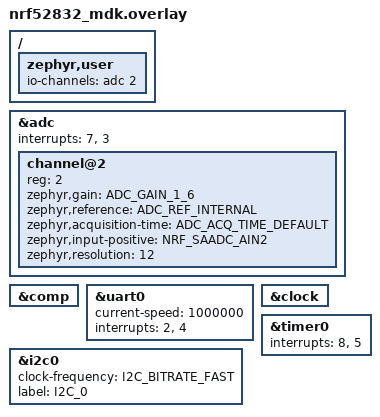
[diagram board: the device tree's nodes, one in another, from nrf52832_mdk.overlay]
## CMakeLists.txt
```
# SPDX-License-Identifier: Apache-2.0

cmake_minimum_required(VERSION 3.20.0)

find_package(Zephyr REQUIRED HINTS $ENV{ZEPHYR_BASE})
project(hello_world)

target_sources(app PRIVATE src/main.c)
target_sources(app PRIVATE src/soft_iic.c)
target_sources(app PRIVATE src/imu_bag.c)
target_sources(app PRIVATE src/timer.c)
target_sources(app PRIVATE src/adc.c)
```

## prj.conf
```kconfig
CONFIG_USE_SEGGER_RTT=y
CONFIG_RTT_CONSOLE=y
CONFIG_LED=y
CONFIG_LOG=y
CONFIG_PWM=y
CONFIG_LOG_MODE_IMMEDIATE=y
CONFIG_I2C=y
CONFIG_I2C_NRFX=y

CONFIG_NRFX_TIMER0=y
CONFIG_ADC=y
CONFIG_SYS_CLOCK_TICKS_PER_SEC=32768
```

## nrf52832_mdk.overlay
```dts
// To get started, press Ctrl+Space to bring up the completion menu and view the available nodes.

// You can also use the buttons in the sidebar to perform actions on nodes.
// Actions currently available include:

// * Enabling / disabling the node
// * Adding the bus to a bus
// * Removing the node
// * Connecting ADC channels

// For more help, browse the DeviceTree documentation at https://docs.zephyrproject.org/latest/guides/dts/index.html
// You can also visit the nRF DeviceTree extension documentation at https://nrfconnect.github.io/vscode-nrf-connect/devicetree/nrfdevicetree.html
/ {
	zephyr,user {
		io-channels = <&adc 2>;
	};
};
&adc {
	#address-cells = <1>;
	#size-cells = <0>;

	channel@2 {
		reg = <2>;
		zephyr,gain = "ADC_GAIN_1_6";
		zephyr,reference = "ADC_REF_INTERNAL";
		zephyr,acquisition-time = <ADC_ACQ_TIME_DEFAULT>;
		zephyr,input-positive = <NRF_SAADC_AIN2>; /* P0.04 */
		zephyr,resolution = <12>;
	};

	status = "okay";
	interrupts = <7>, <3>;
};
&comp {
	status = "okay";
};
&uart0 {
	current-speed = <1000000>;
	interrupts = <2>, <4>;
};

&i2c0 {
	clock-frequency = <I2C_BITRATE_FAST>;
	label = "I2C_0";
};

&clock {
	status = "okay";
};

&timer0 {
	status = "okay";
	interrupts = <8>, <5>;
};
```

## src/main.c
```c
/*
 * Copyright (c) 2012-2014 Wind River Systems, Inc.
 *
 * SPDX-License-Identifier: Apache-2.0
 */
#include "imu_bag.h"
#include "timer.h"
#include "adc.h"
#include "iic_twi.h"
#include "icm_42688.h"
#include "uart.h"
#include <stdio.h>
#include "zephyr/logging/log.h"
#include "nrfx_saadc.h"
#include <zephyr/kernel.h>

//定义IIC的设备名称
struct device *i2c_dev;
#define I2C_DEV_NAME "I2C_0"
//用于进行flag的调用
int flag =0;
//存储一定的AD进而来进行在一定下进行输送
int pd[100];
//用于imu的数据发送
int count =0;
int imu_flag =0;
int b = 0;
int c = 1;
//用于imu_bag计数
int a=0;
char a_a[10];
LOG_MODULE_REGISTER(adc, LOG_LEVEL_DBG);
#define CHANNEL_COUNT 1

static nrfx_saadc_channel_t single_channel = NRFX_SAADC_DEFAULT_CHANNEL_SE(NRF_SAADC_INPUT_AIN2 , 0);
static nrf_saadc_value_t buffer[CHANNEL_COUNT];
/*时钟校准*/
void Bsp_HFCLK_Init_Extern()
{
    NRF_CLOCK->EVENTS_HFCLKSTARTED = 0;
    NRF_CLOCK->TASKS_HFCLKSTART = 1;

    while (NRF_CLOCK->EVENTS_HFCLKSTARTED == 0)
    {
        // Do nothing.
    }
}
int adc_init2(void)
{
	Bsp_HFCLK_Init_Extern();
	nrfx_err_t err;
	//初始化 输入初始化的中断优秀级
	err = nrfx_saadc_init(NRFX_SAADC_DEFAULT_CONFIG_IRQ_PRIORITY);
	//配置通道的属性
	single_channel.channel_config.gain = NRF_SAADC_GAIN1_3;
	//显示通道的采样时间间隔
	LOG_INF("TIME=%d\r\n",single_channel.channel_config.acq_time);
	//nrfx_saadc_channel_config完成通道的配置
	err = nrfx_saadc_channel_config(&single_channel);
	//nrfx_saadc_channels_configured_get();记录了当前配置的通道配置情况
	uint32_t channels_mask = nrfx_saadc_channels_configured_get();
	LOG_INF("ADC channels mask: %d\n", channels_mask);
	//设置通道分辨率为12bit，不使用过采样，事件回调
	err = nrfx_saadc_simple_mode_set(channels_mask, NRF_SAADC_RESOLUTION_12BIT, NRF_SAADC_OVERSAMPLE_DISABLED, NULL);
	printk("this %d\n",err);
	//在开始 SAADC 转换之前，您需要调用此函数来设置一个缓冲区，SAADC 将把采样数据存储到这个缓冲区中。
	err = nrfx_saadc_buffer_set(buffer, CHANNEL_COUNT);
}

int adc_value_get(void)
{
	nrfx_err_t err;
	//nrfx_saadc_offset_calibrate(NULL);校准ADC的偏移量，这里不使用回调函数。
	err = nrfx_saadc_offset_calibrate(NULL);
	//nrfx_saadc_mode_trigger();开始采集数据。
	err = nrfx_saadc_mode_trigger();
	return buffer[0];
}
//转换成电压
int adc_to_voltage(int adc_value)
{
	// return (adc_value * 1800)/4096 ;
	return adc_value ;
}

int main(void)
{
	// //用于存储格式化字符串
	char str[200];
	// //字符指针
	char *P;
	int i=0,offset=0;

	//硬件IIC
	i2c_dev = device_get_binding(I2C_DEV_NAME);
	if(!i2c_dev)
	{
		printk("Failed\n");
		return 0;
	}else{
		printk("SUCCESS\n");
	}
	int err = i2c_configure(i2c_dev, I2C_SPEED_SET(I2C_SPEED_FAST));
    if (err) {
        printk("Failed to configure I2C device: %d\n", err);
        return 0;
    }
    printk("I2C device configured successfully\n");
	// 进行imu与bag的初始化
	imu_bag_init();
	// 进行adc初始化
	adc_init2();
	//进行串口初始化
	uart_init_slef();
	//进行定时器初始化 2k采样率 
 	timer1_init_enable();
	while (1)
	{
			if(imu_flag)
			{
			imu_flag =0;
			imu_bag_read_data();
			// for(i=0;i<100;i++)
			// {
			// 	offset += sprintf(str + offset, "%d,", pd[i]); // 将整数转换为字符串并拼接到str中
			// }
			// P=str;
			// print_uart(P);
			// offset=0;
			// }
		}else{
			//必须加否则会被优化
			c=1;
		}
	}

	// // // //用于存储格式化字符串
	// // char str[200];
	// // // //字符指针
	// // char *P;
	// // int i=0,offset=0;

	// //硬件IIC
	// // i2c_dev = device_get_binding(I2C_DEV_NAME);
	// // if(!i2c_dev)
	// // {
	// // 	printk("Failed\n");
	// // 	return 0;
	// // }else{
	// // 	printk("SUCCESS\n");
	// // }
	// // int err = i2c_configure(i2c_dev, I2C_SPEED_SET(I2C_SPEED_FAST));
    // // if (err) {
    // //     printk("Failed to configure I2C device: %d\n", err);
    // //     return 0;
    // // }
    // // printk("I2C device configured successfully\n");
	// // 进行imu与bag的初始化
	// // imu_bag_init();
	// // 进行adc初始化
	// adc_init();
	// //进行串口初始化
	// uart_init_slef();
	// //进行定时器初始化 2k采样率 
 	// timer1_init_enable();
	// while (1)
	// {
	// 		if(imu_flag)
	// 		{
	// 		imu_flag =0;
	// 		adc_read_data();
	// 		// imu_bag_read_data();
	// 		// for(i=0;i<100;i++)
	// 		// {
	// 		// 	offset += sprintf(str + offset, "%d,", pd[i]); // 将整数转换为字符串并拼接到str中
	// 		// }
	// 		// P=str;
	// 		// print_uart(P);
	// 		// offset=0;
	// 		// }
	// 	}else{
	// 		//必须加否则会被优化
	// 		c=1;
	// 	}
	// }

	// adc_init2();
	// while(1){
	// 	printk("vol=%d\r\n",adc_to_voltage(adc_value_get()));
	// 	k_msleep(100);
	// }
	// adc_init();
	// while(1){
	// 	adc_read_data();
	// 	k_msleep(1);
	// }
	return 0;
}
```

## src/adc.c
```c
/*
 * Copyright (c) 2020 Libre Solar Technologies GmbH
 *
 * SPDX-License-Identifier: Apache-2.0
 */
#include "adc.h"

/* Data of ADC io-channels specified in devicetree. */
static const struct adc_dt_spec adc_channels[] = {
    DT_FOREACH_PROP_ELEM(DT_PATH(zephyr_user), io_channels,
                         DT_SPEC_AND_COMMA)};
static int err;
// static uint32_t count = 0;
static uint16_t buf;
static struct adc_sequence sequence = {
    .buffer = &buf,
    /* buffer size in bytes, not number of samples */
    .buffer_size = sizeof(buf),
};
/**
 * @brief        adc初始化配置
 */
int adc_init(void)
{
    /* Configure channels individually prior to sampling. */
    for (size_t i = 0U; i < ARRAY_SIZE(adc_channels); i++)
    {
        if (!adc_is_ready_dt(&adc_channels[i]))
        {
            printk("ADC controller device %s not ready\n", adc_channels[i].dev->name);
            return 0;
        }

        err = adc_channel_setup_dt(&adc_channels[i]);
        if (err < 0)
        {
            printk("Could not setup channel #%d (%d)\n", i, err);
            return 0;
        }
        (void)adc_sequence_init_dt(&adc_channels[i], &sequence);
    }
    return 1;
}
/**
 * @brief        adc读取数据处理
 */
void adc_read_data(void)
{
	//用于存储格式化字符串
	char str[5];
	//字符指针
	char *ptr;

        // printk("ADC reading[%u]:\n", count++);
        for (size_t i = 0U; i < ARRAY_SIZE(adc_channels); i++)
        {
            int32_t val_mv;

            // printk("- %s, channel %d: ",
            //        adc_channels[i].dev->name,
            //        adc_channels[i].channel_id);
            // (void)adc_sequence_init_dt(&adc_channels[i], &sequence);
            err = adc_read(adc_channels[i].dev, &sequence);
            if (err < 0)
            {
                printk("Could not read (%d)\n", err);
                continue;
            }
            /*
             * If using differential mode, the 16 bit value
             * in the ADC sample buffer should be a signed 2's
             * complement value.
             */
            if (adc_channels[i].channel_cfg.differential)
            {
                val_mv = (int32_t)((int16_t)buf);
            }
            else
            {
                val_mv = (int32_t)buf;
            }
            // printk("ADC%\n" PRId32, val_mv);
            // printk("%d,", val_mv);

            //将整数格式化成指针
		    sprintf(str,"%d,",val_mv);
		    ptr =str;
    		print_uart(ptr);
            // printk("%d,",val_mv);

            //下列代码是将ADC原始值变换为mV
            // err = adc_raw_to_millivolts_dt(&adc_channels[i],
            //                                &val_mv);
            // /* conversion to mV may not be supported, skip if not */
            // if (err < 0)
            // {
            //     printk(" (value in mV not available)\n");
            // }
            // else
            // {
            //     printk(" = %" PRId32 " mV\n", val_mv);
            // }
        }
}
```

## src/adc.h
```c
/**
 * @file         adc.h
 * @details      用于定义adc采样API
 * @author       jjl
 */
#ifndef _ADC_H
#define _ADC_H
/*
===========================
头文件包括
===========================
*/
#include <inttypes.h>
#include <stddef.h>
#include <stdint.h>

#include <zephyr/device.h>
#include <zephyr/devicetree.h>
#include <zephyr/drivers/adc.h>
#include <zephyr/kernel.h>
#include <zephyr/sys/printk.h>
#include <zephyr/sys/util.h>
/*
===========================
宏定义包括
===========================
*/
#if !DT_NODE_EXISTS(DT_PATH(zephyr_user)) || \
    !DT_NODE_HAS_PROP(DT_PATH(zephyr_user), io_channels)
#error "No suitable devicetree overlay specified"
#endif

#define DT_SPEC_AND_COMMA(node_id, prop, idx) \
    ADC_DT_SPEC_GET_BY_IDX(node_id, idx),
/*
===========================
函数申明包括
===========================
*/
/**
 * @brief        adc初始化配置
 */
void adc_init(void);
/**
 * @brief        adc读取数据配置
 */
void adc_read_data(void);
#endif
```

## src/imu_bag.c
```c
/*
 * Copyright (c) 2012-2014 Wind River Systems, Inc.
 *
 * SPDX-License-Identifier: Apache-2.0
 */

#include "imu_bag.h"



uint8_t data[15];
uint8_t icm42688_data[15];
uint8_t lis3dml_data[15];
int16_t acc_data[3] = {0};
int16_t gyro_data[3] = {0};
int16_t mag_data[3] = {0};
uint32_t icm42688_timestamp = 0;
/**
 * @brief Read a sequence of bytes from a sensor registers 重新封装IIC的读取
 * 
 */
static void sensor_register_read(uint8_t sensor_addr, uint8_t reg_addr, uint8_t *data, uint8_t len)
{
	EspI2cReadBytes(sensor_addr, reg_addr, data, len);
}
/**
 * @brief Write a byte to a sensor register 重新封装IIC的写入
 */
static void sensor_register_write_byte(uint8_t sensor_addr, uint8_t reg_addr, uint8_t data)
{
	EspI2cWriteByte(sensor_addr, reg_addr, data);
}
/**
 * @brief icm (imu) 初始化写入命令
 */
void icm_init()
{
	sensor_register_write_byte(ICM_I2C_ADDR, ICM_BANK_SEL, 0);
	k_msleep(10);
	/* 读WHO_AM_I寄存器 */
	sensor_register_read(ICM_I2C_ADDR, ICM_WHO_AM_I, data, 1);
	printk("icm42688 read id:%X\n", data[0]);
	if (data[0] == ICM_ID)
	{
		printk("icm42688 ready!\n");
	}
	else
	{
		printk("icm42688 not found!\n");
	}
	/* 配置寄存器 */
	sensor_register_write_byte(ICM_I2C_ADDR, ICM_DEVICE_CONFIG, 0x01); // 软重启
	k_msleep(10);													   // 等待10ms

	sensor_register_write_byte(ICM_I2C_ADDR, ICM_POWER_MAG, 0x1F); // 开启陀螺仪和加速度计
	k_msleep(100);

	/* 配置FS和ODR */
	// sensor_register_write_byte(ICM_I2C_ADDR, ICM_GYRO_CONFIG0, 0x67); // 250dps,200Hz
	sensor_register_write_byte(ICM_I2C_ADDR, ICM_GYRO_CONFIG0, 0x66); // 250dps,1000Hz
	k_msleep(50);
	// sensor_register_write_byte(ICM_I2C_ADDR, ICM_ACCEL_CONFIG0, 0x47); // 4g, 100Hz（这里应为200Hz）
	sensor_register_write_byte(ICM_I2C_ADDR, ICM_ACCEL_CONFIG0, 0x46); // 4g, 1000Hz
	k_msleep(50);
	sensor_register_write_byte(ICM_I2C_ADDR, ICM_GYRO_ACCEL_CONFIG0, 0x55); // 20Hz BW
	k_msleep(50);
	printk("icm42688 gyr and acc config finished!");

	/* 开启时间戳 */
	sensor_register_write_byte(ICM_I2C_ADDR, ICM_TMST_CONFIG, 0x33);
	k_msleep(50);
}
/**
 * @brief lis3dml (bag) 初始化写入命令
 */
void lis3dml_init()
{
	/* 读WHO_AM_I寄存器 */
	sensor_register_read(LIS3MDL_I2C_ADDR_G, LIS3MDL_WHO_AM_I, data, 1);
	printk("lis3dml read id:%X\n", data[0]);
	if (data[0] == LIS3MDL_ID)
	{
		printk("lis3dml ready!");
	}
	else
	{
		printk("lis3dml not found!");
	}
	/* 软重启 */
	sensor_register_write_byte(LIS3MDL_I2C_ADDR_G, LIS3MDL_CTRL_REG2, 0x04);
	/* 延时 */
	k_msleep(50);
	/* 配置BDU */
	sensor_register_write_byte(LIS3MDL_I2C_ADDR_G, LIS3MDL_CTRL_REG5, 0x40);
	/* 延时 */
	k_msleep(50);
	/* 配置 */
	// sensor_register_write_byte(LIS3MDL_I2C_ADDR_G, LIS3MDL_CTRL_REG1, 0x60 | 0x1C); // X、Y轴high performance，80Hz(这个不太对应该是ultra-high-perfermance)
	sensor_register_write_byte(LIS3MDL_I2C_ADDR_G, LIS3MDL_CTRL_REG1, 0x40 | 0x02); // X、Y轴high performance，300H performance，80Hz
	sensor_register_write_byte(LIS3MDL_I2C_ADDR_G, LIS3MDL_CTRL_REG2, 0x00);		// ±4 gauss
	sensor_register_write_byte(LIS3MDL_I2C_ADDR_G, LIS3MDL_CTRL_REG3, 0x00);		// 连续转换模式
	sensor_register_write_byte(LIS3MDL_I2C_ADDR_G, LIS3MDL_CTRL_REG4, 0x0C);		// Z轴high performance
}
/**
 * @brief imu与bag 初始化程序
 */
 void imu_bag_init(void)
{
	I2cInit();
	/* 初始化icm42688 */
	icm_init();
	/* 初始化lis3dml */
	lis3dml_init();
}
/**
 * @brief imu与bag 读取程序
 */
void imu_bag_read_data( void)
{
	//用于存储格式化字符串
	char str_42688[120];
	char str_3dml[120];
	// 字符指针
	char *ptr_42688;
	char *ptr_3dml;

		/* ICM-42688-P 读数据 */
		sensor_register_write_byte(ICM_I2C_ADDR, ICM_BANK_SEL, 0);
		sensor_register_write_byte(ICM_I2C_ADDR, ICM_SIGNAL_PATH_RESET, 0x04);
		sensor_register_read(ICM_I2C_ADDR, ICM_ACCEL_DATA_X1, icm42688_data, 12);
		sensor_register_write_byte(ICM_I2C_ADDR, ICM_BANK_SEL, 1);
		// k_usleep(10);
		sensor_register_read(ICM_I2C_ADDR, ICM_TMSTVAL0, icm42688_data + 12, 3);

		/* LIS3DML读数据 */
		sensor_register_read(LIS3MDL_I2C_ADDR_G, LIS3MDL_OUT_X_L, lis3dml_data, 6);

		/* ICM42688打印数据 */
		acc_data[0] = (icm42688_data[0] << 8) + icm42688_data[1];
		acc_data[1] = (icm42688_data[2] << 8) + icm42688_data[3];
		acc_data[2] = (icm42688_data[4] << 8) + icm42688_data[5];

		gyro_data[0] = (icm42688_data[6] << 8) + icm42688_data[7];
		gyro_data[1] = (icm42688_data[8] << 8) + icm42688_data[9];
		gyro_data[2] = (icm42688_data[10] << 8) + icm42688_data[11];

		icm42688_timestamp = (icm42688_data[14] << 16) + (icm42688_data[13] << 8) + icm42688_data[12];

		// /* LIS3DML打印数据 */
		mag_data[0] = lis3dml_data[0] + (lis3dml_data[1] << 8);
		mag_data[1] = lis3dml_data[2] + (lis3dml_data[3] << 8);
		mag_data[2] = lis3dml_data[4] + (lis3dml_data[5] << 8);

		// 将上面两行数据直接用串口打印
		// 将整数格式化成指针
		sprintf(str_42688,"icm42688, acc_x:%d, acc_y:%d, acc_z:%d, gyr_x:%d, gyr_y:%d, gyr_z:%d, tick:%ld \n",acc_data[0], acc_data[1], acc_data[2],
			   gyro_data[0], gyro_data[1], gyro_data[2],(long int)icm42688_timestamp);
		// sprintf(str_42688,"tick:%ld\n",(long int)icm42688_timestamp);
		ptr_42688 = str_42688;
		print_uart(ptr_42688);
		// memset(str_42688,0,sizeof(str_42688));

		sprintf(str_3dml,"lis3dml, mag_x:%d, mag_y:%d, mag_z:%d\n",
			   mag_data[0], mag_data[1], mag_data[2]);
		ptr_3dml = str_3dml;
		print_uart(ptr_3dml);
		// memset(str_3dml,0,sizeof(str_3dml));
}
```

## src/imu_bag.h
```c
/**
 * @file         imu_bag.h
 * @details      用于定义imu与bag联合程序
 * @author       jjl
 */
#ifndef _IMU_BAG_H
#define _IMU_BAG_H

/*
===========================
头文件包括
===========================
*/
#include <stdio.h>
#include <zephyr/kernel.h>
#include <zephyr/drivers/gpio.h>
#include <nrfx_gpiote.h>
#include "soft_iic.h"
#include "icm_42688.h"
#include "lis3dml.h"
/*
===========================
宏定义
===========================
*/
/* 1000 msec = 1 sec */
#define SLEEP_TIME_MS 1000
/*
===========================
变量声明
===========================
*/
extern uint8_t icm42688_data[15];
extern uint8_t lis3dml_data[15];
extern int16_t acc_data[3];
extern int16_t gyro_data[3];
extern int16_t mag_data[3];
extern uint32_t icm42688_timestamp;
/*
===========================
函数声明
===========================
*/
/**
 * @brief icm (imu) 初始化写入命令
 */
void icm_init();
/**
 * @brief lis3dml (bag) 初始化写入命令
 */
void lis3dml_init();
/**
 * @brief imu与bag 初始化程序
 */
void imu_bag_init(void);
/**
 * @brief imu与bag 读取程序
 */
void imu_bag_read_data(void);

#endif
```

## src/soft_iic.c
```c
#include "soft_iic.h"
#include "unistd.h"

#define I2C_MASTER_WRITE 0
#define I2C_MASTER_READ 1

void I2cInit()
{
    // esp_log_level_set("gpio", ESP_LOG_NONE);
    // const gpio_config_t io_config = {
    //     .intr_type = GPIO_INTR_DISABLE,
    //     .mode = GPIO_MODE_OUTPUT,
    //     .pull_down_en = GPIO_PULLDOWN_DISABLE,
    //     .pull_up_en = GPIO_PULLUP_ENABLE,
    //     .pin_bit_mask = (1ULL << I2C_SCL_PIN) | (1ULL << I2C_SDA_PIN)};
    // gpio_config(&io_config);
    nrf_gpio_cfg_output(I2C_SCL_PIN);
    nrf_gpio_cfg_output(I2C_SDA_PIN);

    I2C_SDA_HIGH;
    I2C_SCL_HIGH;
}

void I2cSdaIn(void)
{
    nrf_gpio_cfg_input(I2C_SDA_PIN, NRF_GPIO_PIN_NOPULL);
    // return 0;
}

void I2cSdaOut(void)
{
    nrf_gpio_cfg_output(I2C_SDA_PIN);
    // return 0;
}

void I2cStart(void)
{
    I2cSdaOut();
    I2C_SDA_HIGH;
    I2C_SCL_HIGH;
    k_usleep(4);
    I2C_SDA_LOW;
    k_usleep(4);
    I2C_SCL_LOW;
}

void I2cStop(void)
{
    I2cSdaOut();
    I2C_SCL_LOW;
    I2C_SDA_LOW;
    k_usleep(4);
    I2C_SCL_HIGH;
    k_usleep(4);
    I2C_SDA_HIGH;
    k_usleep(4);
}

uint8_t I2cWaitAck(void)
{
    uint8_t ErrTime = 0;

    I2C_SDA_HIGH;
    k_usleep(2);
    I2cSdaIn();
    k_usleep(2);
    I2C_SCL_HIGH;
    k_usleep(2);
    while (I2C_SDA == 1)
    {
        ErrTime++;
        if (ErrTime > 200)
        {
            I2cStop();
            return 1;
        }
    }
    I2C_SCL_LOW;
    return 0;
}

void I2cAck(void)
{
    I2C_SCL_LOW;
    I2cSdaOut();
    I2C_SDA_LOW;
    k_usleep(2);
    I2C_SCL_HIGH;
    k_usleep(2);
    I2C_SCL_LOW;
}

void I2cNack(void)
{
    I2C_SCL_LOW;
    I2cSdaOut();
    I2C_SDA_HIGH;
    k_usleep(2);
    I2C_SCL_HIGH;
    k_usleep(2);
    I2C_SCL_LOW;
}

void I2cWriteByte(uint8_t Data)
{
    uint8_t i;

    I2cSdaOut();
    I2C_SCL_LOW;
    for (i = 0; i < 8; i++)
    {
        if ((Data << i) & 0x80)
        {
            I2C_SDA_HIGH;
        }
        else
        {
            I2C_SDA_LOW;
        }
        k_usleep(2);
        I2C_SCL_HIGH;
        k_usleep(2);
        I2C_SCL_LOW;
        k_usleep(2);
    }
}

uint8_t I2cReadByte(uint8_t isAck)
{
    uint8_t i;
    uint8_t Data = 0x0;

    I2cSdaIn();

    for (i = 0; i < 8; i++)
    {
        I2C_SCL_LOW;
        k_usleep(2);
        I2C_SCL_HIGH;
        Data <<= 1;
        if (I2C_SDA == 1)
        {
            Data++;
        }
        k_usleep(1);
    }
    if (isAck)
    {
        I2cNack();
    }
    else
    {
        I2cAck();
    }
    return Data;
}

void EspI2cWriteByte(uint8_t dev_addr, uint8_t reg_addr, uint8_t write_data)
{
    // I2cStart();
    // I2cWriteByte((dev_addr << 1) | I2C_MASTER_WRITE);
    // I2cWaitAck();
    // I2cWriteByte(reg_addr);
    // I2cWaitAck();
    // I2cWriteByte(write_data);
    // I2cWaitAck();
    // I2cStop();

    //以下是重新调用硬件IIC
    struct i2c_msg msgs[2];
	msgs[0].buf = &reg_addr;
	msgs[0].len = 1;
	msgs[0].flags = I2C_MSG_WRITE;
	msgs[1].buf = &write_data;
	msgs[1].len = 1;
	msgs[1].flags = I2C_MSG_WRITE | I2C_MSG_STOP;

	i2c_transfer(i2c_dev, msgs, 2, dev_addr);
}

void EspI2cReadByte(uint8_t dev_addr, uint8_t reg_addr, uint8_t *read_data)
{
    I2cStart();
    I2cWriteByte((dev_addr << 1) | I2C_MASTER_WRITE);
    I2cWaitAck();
    I2cWriteByte(reg_addr);
    I2cWaitAck();

    I2cStart();
    I2cWriteByte((dev_addr << 1) | I2C_MASTER_READ);
    *read_data = I2cReadByte(NACK_VAL);
    I2cStop();
}

void EspI2cWriteBytes(uint8_t dev_addr, uint8_t reg_addr, uint8_t *write_data, uint8_t write_len)
{
    uint8_t i;

    I2cStart();

    I2cWriteByte((dev_addr << 1) | I2C_MASTER_WRITE);
    I2cWaitAck();

    I2cWriteByte(reg_addr);
    I2cWaitAck();

    for (i = 0; i < write_len; i++)
    {
        I2cWriteByte(write_data[i]);
        I2cWaitAck();
    }
    I2cStop();
}

void EspI2cReadBytes(uint8_t dev_addr, uint8_t reg_addr, uint8_t *read_data, uint8_t read_len)
{
    // uint8_t i = 0;

    // I2cStart();

    // I2cWriteByte((dev_addr << 1) | I2C_MASTER_WRITE);
    // I2cWaitAck();

    // I2cWriteByte(reg_addr);
    // I2cWaitAck();

    // I2cStart();
    // I2cWriteByte((dev_addr << 1) | I2C_MASTER_READ);
    // I2cWaitAck();

    // if (read_len > 1)
    // {
    //     for (i = 0; i < read_len - 1; i++)
    //     {
    //         read_data[i] = I2cReadByte(ACK_VAL);
    //         // ets_delay_us(10);
    //     }
    // }
    // read_data[i] = I2cReadByte(NACK_VAL);

    // I2cStop();


    //以下是调用硬件IIC
    i2c_write_read(i2c_dev, dev_addr,&reg_addr, 1, read_data ,read_len);
}

void I2cDetect(void)
{
    uint8_t i;
    uint8_t j;
    uint8_t address;
    uint8_t ret = 0;

    printf("     0  1  2  3  4  5  6  7  8  9  a  b  c  d  e  f\r\n");
    for (i = 0; i < 128; i += 16)
    {
        printf("%02x: ", i);
        for (j = 0; j < 16; j++)
        {
            fflush(stdout);
            address = i + j;

            I2cStart();
            I2cWriteByte((address << 1) | I2C_MASTER_WRITE);
            ret = I2cWaitAck();
            I2cStop();

            if (ret == 0)
            {
                printf("%02x ", address);
            }
            else
            {
                printf("-- ");
            }
        }
        printf("\r\n");
    }
}
```

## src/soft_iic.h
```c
#ifndef _SOFT_IIC_H_
#define _SOFT_IIC_H_

#include <stdio.h>
#include <zephyr/kernel.h>
#include <zephyr/drivers/gpio.h>
#include <nrfx_gpiote.h>
//硬件IIC所需头文件
#include "iic_twi.h"
#define ACK_VAL 0x0
#define NACK_VAL 0x1
#define ACK_CHECK_EN 0x1
#define ACK_CHECK_DIS 0x0

// #define ESP32_GPIO_OUT_W1TS(gpio_num) (GPIO.out_w1ts = (0x01 << gpio_num)) // gpio_num:0 ~ 31    GPIO OUT HIGH
// #define ESP32_GPIO_OUT_W1TC(gpio_num) (GPIO.out_w1tc = (0x01 << gpio_num)) // gpio_num:0 ~ 31    GPIO OUT LOW

// #define ESP32_GPIO_OUT1_W1TS(gpio_num) (GPIO.out1_w1ts.data = (0x01 << (gpio_num - 32))) // gpio_num:32 ~ 39   GPIO OUT HIGH
// #define ESP32_GPIO_OUT1_W1TC(gpio_num) (GPIO.out1_w1tc.data = (0x01 << (gpio_num - 32))) // gpio_num:32 ~ 39   GPIO OUT LOW

#define ESP32_GPIO_IN(gpio_num) nrf_gpio_pin_read(gpio_num) // gpio_num:0 ~ 31    GPIO IN VALUE
// #define ESP32_GPIO_IN1(gpio_num) ((GPIO.in1.data >> gpio_num) & 0x1) // gpio_num:32 ~ 39   GPIO IN VALUE

#define GpioReadBit(gpio_num) ESP32_GPIO_IN(gpio_num)

#define GpioSetBit(gpio_num) nrf_gpio_pin_write(gpio_num, 1)

#define GpioResetBit(gpio_num) nrf_gpio_pin_write(gpio_num, 0)

#define I2C_SCL_PIN 27
#define I2C_SDA_PIN 26

// #define I2C_SCL_PIN 5  /*!< GPIO number used for I2C master clock */
// #define I2C_SDA_PIN 18 /*!< GPIO number used for I2C master data  */

#define I2C_SDA_HIGH GpioSetBit(I2C_SDA_PIN)
#define I2C_SDA_LOW GpioResetBit(I2C_SDA_PIN)

#define I2C_SCL_HIGH GpioSetBit(I2C_SCL_PIN)
#define I2C_SCL_LOW GpioResetBit(I2C_SCL_PIN)

#define I2C_SDA GpioReadBit(I2C_SDA_PIN)

//定义的IIC设备标签（硬件IIC所需）
extern struct device *i2c_dev;

// #define I2C_SDA				                gpio_get_level(I2C_SDA_PIN)

void I2cInit(void);

void I2cStart(void);

void I2cStop(void);

uint8_t I2cWaitAck(void);

void I2cAck(void);

void I2cNack(void);

void I2cWriteByte(uint8_t Data);

uint8_t I2cReadByte(uint8_t isAck);

void EspI2cWriteByte(uint8_t dev_addr,
                     uint8_t reg_addr,
                     uint8_t write_data);

void EspI2cReadByte(uint8_t dev_addr,
                    uint8_t reg_addr,
                    uint8_t *read_data);

void EspI2cWriteBytes(uint8_t dev_addr,
                      uint8_t reg_addr,
                      uint8_t *write_data,
                      uint8_t write_len);

void EspI2cReadBytes(uint8_t dev_addr,
                     uint8_t reg_addr,
                     uint8_t *read_data,
                     uint8_t read_len);

void I2cDetect(void);

#endif
```

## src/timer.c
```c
#include "timer.h"
#include "adc.h"
/**
 * @brief 定时器事件处理函数
 *
 * @param[in] event_type 定时器的事件类型.
 * @param[in] p_context  传递的字节数
 */
extern int flag,count,imu_flag,pd[100],a;
extern char a_a[10];
void timer_handler(nrf_timer_event_t event_type, void * p_context)
{

    if(event_type == NRF_TIMER_EVENT_COMPARE0)
    {
        // flag =(flag+1)%2;
        // count++;
        // pd[count-1] = adc_value_get();
        // if(count%20==0)
        // {
        // count = count%20;
        imu_flag =(imu_flag+1)%2;
        // print_uart("A\n");
        // a++;
		// a=a%100;
		// sprintf(a_a,"%d\n",a);
		// print_uart(a_a);
        // }

    }
}

/**
 * @brief 定时器相关配置及启动
 *
 * @return Nothing.
 */
void timer1_init_enable(void)
{
    nrfx_err_t status;
    (void)status;
    nrfx_timer_t timer_inst = NRFX_TIMER_INSTANCE(TIMER_INST_IDX);
    //用于获取定时器的基频值
    uint32_t base_frequency = NRF_TIMER_BASE_FREQUENCY_GET(timer_inst.p_reg);
    //配置定时器的基本属性
    nrfx_timer_config_t config = NRFX_TIMER_DEFAULT_CONFIG(base_frequency);
    //打印定时器的频率值
    printk("this is time %d\n",base_frequency);
    config.bit_width = NRF_TIMER_BIT_WIDTH_32;
    config.p_context = "Some context";
    printk("config.frequnecy is %d",config.frequency);
    printf("config.mode is %d",config.mode);
    //初始化定时器
    status = nrfx_timer_init(&timer_inst, &config, timer_handler);
    NRFX_ASSERT(status == NRFX_SUCCESS);

#if defined(__ZEPHYR__)
    IRQ_DIRECT_CONNECT(NRFX_IRQ_NUMBER_GET(NRF_TIMER_INST_GET(TIMER_INST_IDX)), IRQ_PRIO_LOWEST,
                       NRFX_TIMER_INST_HANDLER_GET(TIMER_INST_IDX), 0);
#endif
    //清除定时器
    nrfx_timer_clear(&timer_inst);
    //直接通过转换来成计数器通道的配置数字，极大的简便了定时器的工作(这里可选择ms还是us)
    // uint32_t desired_ticks = nrfx_timer_us_to_ticks(&timer_inst, TIME_TO_WAIT_US);

    uint32_t desired_ticks=nrfx_timer_ms_to_ticks(&timer_inst, TIME_TO_WAIT_MS);
    printk("this is desired %d",desired_ticks);

    //用于使能定时器比较通道，使能比较中断，设置触发比较寄存器CC[n],根据通道来停止任务（或者清零）
    nrfx_timer_extended_compare(&timer_inst, NRF_TIMER_CC_CHANNEL0, desired_ticks,
                                NRF_TIMER_SHORT_COMPARE0_CLEAR_MASK, true);
    //使能定时器
    nrfx_timer_enable(&timer_inst);
    printk("timer is ok\n");
}
```

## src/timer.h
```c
/**
 * @file         timer.h
 * @details      用于timer 各类定义
 * @author       jjl
 */
#ifndef _TIMER_H
#define _TIMER_H

/*
===========================
头文件包括
===========================
*/
#include <nrfx_timer.h>
#include "imu_bag.h"
#include "adc.h"
#include <stdio.h>
#include <zephyr/kernel.h>
/*
===========================
宏定义
===========================
*/
/** @brief 选用哪个型号的定时器 */
#define TIMER_INST_IDX 0

/** @brief 等待时间以us为单位*/
#define TIME_TO_WAIT_US 500UL

/** @brief 等待时间以ms为单位*/
#define TIME_TO_WAIT_MS 5UL
/*
===========================
变量声明
===========================
*/
/*
===========================
函数声明
===========================
*/
/**
 * @brief 定时器事件处理函数
 *
 * @param[in] event_type 定时器的事件类型.
 * @param[in] p_context  传递的字节数
 */
void timer_handler(nrf_timer_event_t event_type, void * p_context);
/**
 * @brief 定时器相关配置及开启
 *
 * @return Nothing.
 */
void timer1_init_enable(void);

#endif
```
